# F28x7x_mem_cfg_regs register map
Vendor: Texas Instruments
Peripheral module from a debugger description file (folder C2000).
Address unit: 16 bits
Registers are 32-bit, read-write, no defined reset value unless marked. A register's access mark holds for its fields unless they carry their own. Offsets are as the file gives them; lines under a group give offsets from that group; [hi:lo] are bit positions; {n}, {i} and the like mark numbered series; 'fields as' and 'values as' point back to an identical list; <NAME> marks a mode.

## MEM_CFG_REGS
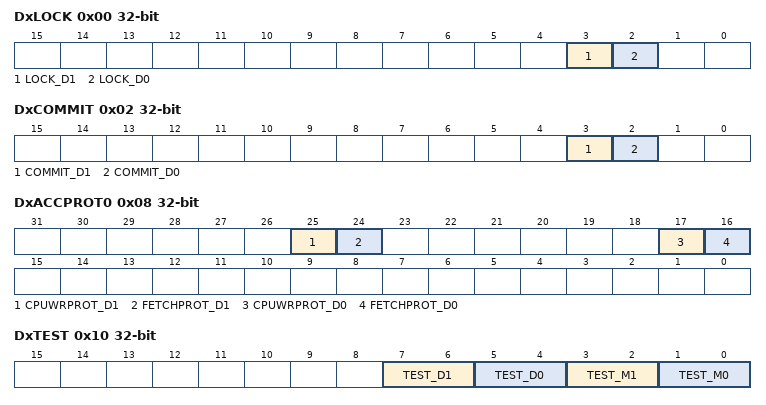
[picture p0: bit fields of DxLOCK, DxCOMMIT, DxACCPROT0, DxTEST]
0x00 DxLOCK — Dedicated RAM Config Lock Register
  [3] LOCK_D1 — D1 RAM access protection and master select fields lock bit
  [2] LOCK_D0 — D0 RAM access protection and master select fields lock bit
0x02 DxCOMMIT — Dedicated RAM Config Lock Commit Register
  [3] COMMIT_D1 — D1 RAM access protection and master select permanent lock
  [2] COMMIT_D0 — D0 RAM access protection and master select permanent lock
0x08 DxACCPROT0 — Dedicated RAM Config Register
  [25] CPUWRPROT_D1 — CPU WR Protection For D1 RAM
  [24] FETCHPROT_D1 — Fetch Protection For D1 RAM
  [17] CPUWRPROT_D0 — CPU WR Protection For D0 RAM
  [16] FETCHPROT_D0 — Fetch Protection For D0 RAM
0x10 DxTEST — Dedicated RAM TEST Register
  [7:6] TEST_D1 — Selects the different modes for D1 RAM
  [5:4] TEST_D0 — Selects the different modes for D0 RAM
  [3:2] TEST_M1 — Selects the different modes for M1 RAM
  [1:0] TEST_M0 — Selects the different modes for M0 RAM
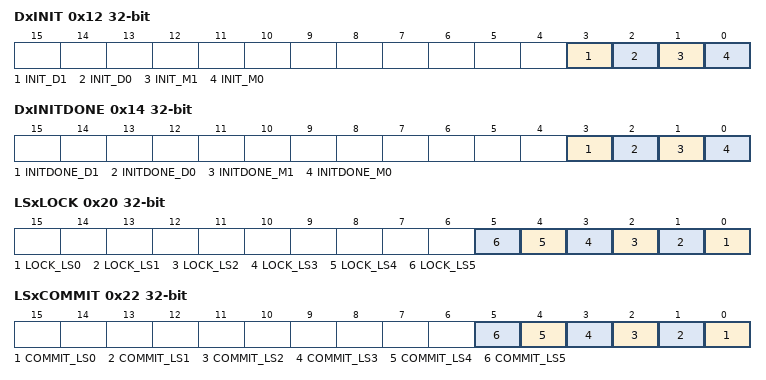
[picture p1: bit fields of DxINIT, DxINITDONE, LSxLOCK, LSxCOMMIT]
0x12 DxINIT — Dedicated RAM Init Register
  [3] INIT_D1 — RAM Initialization control for D1 RAM.
  [2] INIT_D0 — RAM Initialization control for D0 RAM.
  [1] INIT_M1 — RAM Initialization control for M1 RAM.
  [0] INIT_M0 — RAM Initialization control for M0 RAM.
0x14 DxINITDONE — Dedicated RAM InitDone Status Register
  [3] INITDONE_D1 — RAM Initialization status for D1 RAM.
  [2] INITDONE_D0 — RAM Initialization status for D0 RAM.
  [1] INITDONE_M1 — RAM Initialization status for M1 RAM.
  [0] INITDONE_M0 — RAM Initialization status for M0 RAM.
0x20 LSxLOCK — Local Shared RAM Config Lock Register
  [n] LOCK_LS{n} (n=0..5) — LS{n} RAM access protection and master select fields lock bit
0x22 LSxCOMMIT — Local Shared RAM Config Lock Commit Register
  [n] COMMIT_LS{n} (n=0..5) — LS{n} RAM access protection and master select permanent lock
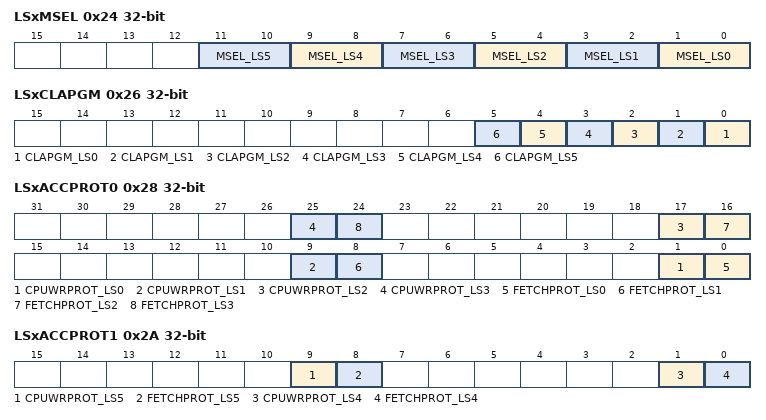
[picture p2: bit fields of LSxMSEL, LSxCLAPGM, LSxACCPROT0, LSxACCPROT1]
0x24 LSxMSEL — Local Shared RAM Master Sel Register
  [2n+1:2n] MSEL_LS{n} (n=0..5) — Master Select for LS{n} RAM
0x26 LSxCLAPGM — Local Shared RAM Prog/Exe control Register
  [n] CLAPGM_LS{n} (n=0..5) — Selects LS{n} RAM as program vs data memory for CLA
0x28 LSxACCPROT0 — Local Shared RAM Config Register 0
  [8n+1] CPUWRPROT_LS{n} (n=0..3) — CPU WR Protection For LS{n} RAM
  [8n] FETCHPROT_LS{n} (n=0..3) — Fetch Protection For LS{n} RAM
0x2A LSxACCPROT1 — Local Shared RAM Config Register 1
  [9] CPUWRPROT_LS5 — CPU WR Protection For LS5 RAM
  [8] FETCHPROT_LS5 — Fetch Protection For LS5 RAM
  [1] CPUWRPROT_LS4 — CPU WR Protection For LS4 RAM
  [0] FETCHPROT_LS4 — Fetch Protection For LS4 RAM
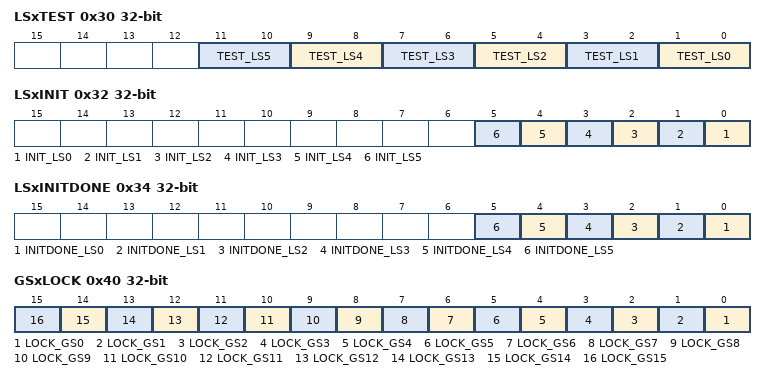
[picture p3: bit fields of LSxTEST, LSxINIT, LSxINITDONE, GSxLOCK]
0x30 LSxTEST — Local Shared RAM TEST Register
  [2n+1:2n] TEST_LS{n} (n=0..5) — Selects the different modes for LS{n} RAM
0x32 LSxINIT — Local Shared RAM Init Register
  [n] INIT_LS{n} (n=0..5) — RAM Initialization control for LS{n} RAM.
0x34 LSxINITDONE — Local Shared RAM InitDone Status Register
  [n] INITDONE_LS{n} (n=0..5) — RAM Initialization status for LS{n} RAM.
0x40 GSxLOCK — Global Shared RAM Config Lock Register
  [n] LOCK_GS{n} (n=0..15) — GS{n} RAM access protection and master select fields lock bit
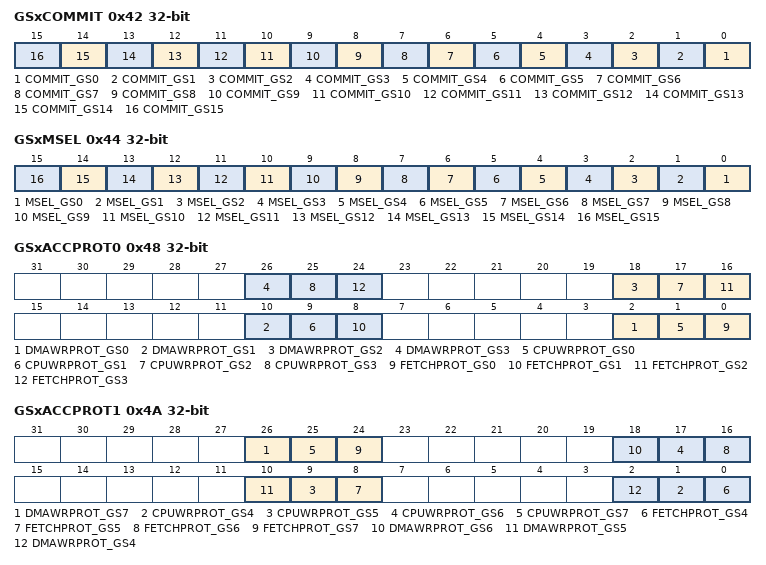
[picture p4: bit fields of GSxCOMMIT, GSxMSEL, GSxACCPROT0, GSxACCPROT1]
0x42 GSxCOMMIT — Global Shared RAM Config Lock Commit Register
  [n] COMMIT_GS{n} (n=0..15) — GS{n} RAM access protection and master select permanent lock
0x44 GSxMSEL — Global Shared RAM Master Sel Register
  [n] MSEL_GS{n} (n=0..15) — Master Select for GS{n} RAM
0x48 GSxACCPROT0 — Global Shared RAM Config Register 0
  [8n+2] DMAWRPROT_GS{n} (n=0..3) — DMA WR Protection For GS{n} RAM
  [8n+1] CPUWRPROT_GS{n} (n=0..3) — CPU WR Protection For GS{n} RAM
  [8n] FETCHPROT_GS{n} (n=0..3) — Fetch Protection For GS{n} RAM
0x4A GSxACCPROT1 — Global Shared RAM Config Register 1
  [26] DMAWRPROT_GS7 — DMA WR Protection For GS7RAM
  [8n-31] CPUWRPROT_GS{n} (n=4..7) — CPU WR Protection For GS{n} RAM
  [8n-32] FETCHPROT_GS{n} (n=4..7) — Fetch Protection For GS{n} RAM
  [18] DMAWRPROT_GS6 — DMA WR Protection For GS6RAM
  [10] DMAWRPROT_GS5 — DMA WR Protection For GS5RAM
  [2] DMAWRPROT_GS4 — DMA WR Protection For GS4 RAM
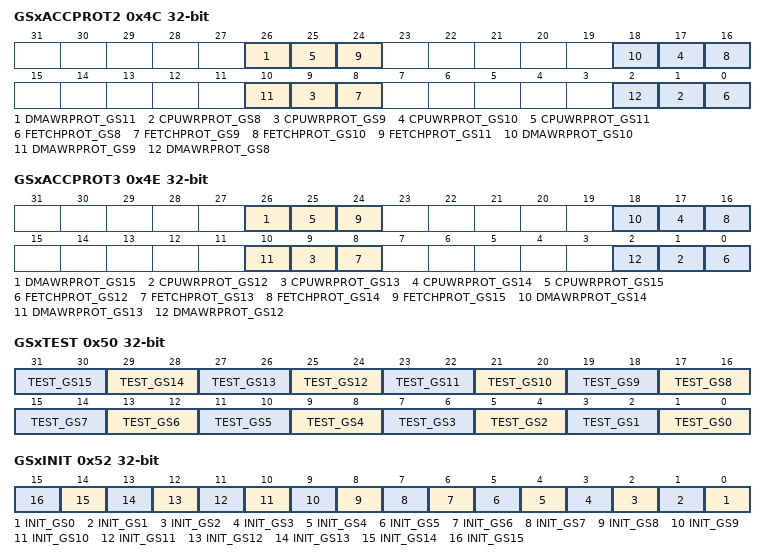
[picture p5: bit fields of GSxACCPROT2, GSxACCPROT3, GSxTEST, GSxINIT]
0x4C GSxACCPROT2 — Global Shared RAM Config Register 2
  [26] DMAWRPROT_GS11 — DMA WR Protection For GS11RAM
  [8n-63] CPUWRPROT_GS{n} (n=8..11) — CPU WR Protection For GS{n} RAM
  [8n-64] FETCHPROT_GS{n} (n=8..11) — Fetch Protection For GS{n} RAM
  [18] DMAWRPROT_GS10 — DMA WR Protection For GS10RAM
  [10] DMAWRPROT_GS9 — DMA WR Protection For GS9RAM
  [2] DMAWRPROT_GS8 — DMA WR Protection For GS8 RAM
0x4E GSxACCPROT3 — Global Shared RAM Config Register 3
  [26] DMAWRPROT_GS15 — DMA WR Protection For GS15RAM
  [8n-95] CPUWRPROT_GS{n} (n=12..15) — CPU WR Protection For GS{n} RAM
  [8n-96] FETCHPROT_GS{n} (n=12..15) — Fetch Protection For GS{n} RAM
  [18] DMAWRPROT_GS14 — DMA WR Protection For GS14RAM
  [10] DMAWRPROT_GS13 — DMA WR Protection For GS13RAM
  [2] DMAWRPROT_GS12 — DMA WR Protection For GS12 RAM
0x50 GSxTEST — Global Shared RAM TEST Register
  [2n+1:2n] TEST_GS{n} (n=0..15) — Selects the different modes for GS{n} RAM
0x52 GSxINIT — Global Shared RAM Init Register
  [n] INIT_GS{n} (n=0..15) — RAM Initialization control for GS{n} RAM.
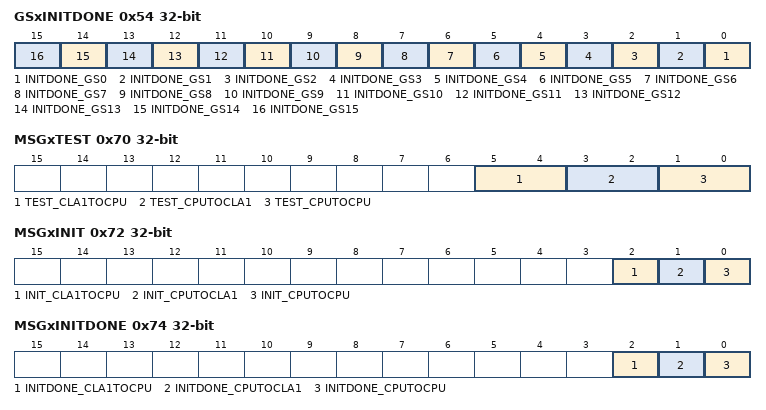
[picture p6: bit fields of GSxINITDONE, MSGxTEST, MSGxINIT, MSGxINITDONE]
0x54 GSxINITDONE — Global Shared RAM InitDone Status Register
  [n] INITDONE_GS{n} (n=0..15) — RAM Initialization status for GS{n} RAM.
0x70 MSGxTEST — Message RAM TEST Register
  [5:4] TEST_CLA1TOCPU — CLA1 to CPU MSG RAM Mode Select
  [3:2] TEST_CPUTOCLA1 — CPU to CLA1 MSG RAM Mode Select
  [1:0] TEST_CPUTOCPU — CPU to CPU Mode Select
0x72 MSGxINIT — Message RAM Init Register
  [2] INIT_CLA1TOCPU — Initialization control for CLA1TOCPU MSG RAM
  [1] INIT_CPUTOCLA1 — Initialization control for CPUTOCLA1 MSG RAM
  [0] INIT_CPUTOCPU — Initialization control for CPU to CPU MSG RAM
0x74 MSGxINITDONE — Message RAM InitDone Status Register
  [2] INITDONE_CLA1TOCPU — Initialization status for CLA1 to CPU MSG RAM
  [1] INITDONE_CPUTOCLA1 — Initialization status for CPU to CLA1 MSG RAM
  [0] INITDONE_CPUTOCPU — Initialization status for CPU to CPU MSG RAM
